# RE01_256KB register map
Vendor: Renesas Electronics Corporation; Series: RE01; File version: 1.00.01
CPU: CM0PLUS r0p1, little endian, MPU, no FPU, VTOR, 2 interrupt priority bits, 32 interrupts
Registers are 8-bit, read-write, reset 0x0 unless marked. A register's access mark holds for its fields unless they carry their own. Offsets are from the block's base; [hi:lo] are bit positions; {n}, {i} and the like mark numbered series; 'fields as' and 'values as' point back to an identical list.

## DMA — DMAC Module Activation
Base 0x40005200
0x00 DMAST — DMA Module Activation Register
  [0] DMST — DMAC Operation Enable
    0=DMAC activation is disabled; 1=DMAC activation is enabled

## DTC — Data Transfer Controller
Base 0x40005400
0x00 DTCCR reset 0x8 — DTC Control Register
  [4] RRS — DTC Transfer Information Read Skip Enable
    0=Transfer information read is not skipped; 1=Transfer information read is skipped when vector numbers match
0x04 DTCVBR 32-bit — DTC Vector Base Register
0x0C DTCST — DTC Module Start Register
  [0] DTCST — DTC Module Start
    0=DTC module stopped; 1=DTC module started
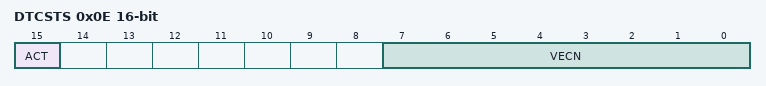
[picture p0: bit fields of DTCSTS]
0x0E DTCSTS 16-bit ro — DTC Status Register
  [15] ACT — DTC Active Flag
    0=DTC transfer operation is not in progress; 1=DTC transfer operation is in progress
  [7:0] VECN — DTC-Activating Vector Number Monitoring

## DBG — Debug Function
Base 0x4001B000
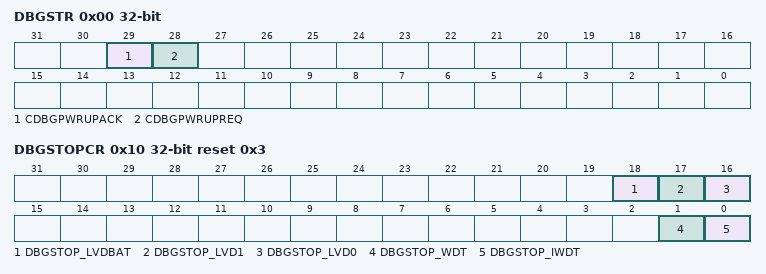
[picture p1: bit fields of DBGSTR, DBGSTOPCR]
0x00 DBGSTR 32-bit ro — Debug Status Register
  [29] CDBGPWRUPACK — Debug power-up acknowledge
    0=Debug power-up request is not acknowledged; 1=Debug power-up request is acknowledged
  [28] CDBGPWRUPREQ — Debug power-up request
    0=OCD is not requesting debug power up; 1=OCD is requesting debug power up
0x10 DBGSTOPCR 32-bit reset 0x3 — Debug Stop Control Register
  [18] DBGSTOP_LVDBAT — Mask bit for LVDBAT reset/interrupt
    0=Enable LVDBAT reset/interrupt; 1=Mask LVDBAT reset/interrupt
  [17] DBGSTOP_LVD1 — Mask bit for LVD1 reset/interrupt
    0=Enable LVD1 reset/interrupt; 1=Mask LVD1 reset/interrupt
  [16] DBGSTOP_LVD0 — Mask bit for LVD0 reset
    0=Enable LVD0 reset; 1=Mask LVD0 reset
  [1] DBGSTOP_WDT — Mask bit for WDT reset/interrupt
    0=Enable WDT reset/interrupt; 1=Mask WDT reset/interrupt and stop WDT count when CPU is in OCD break mode
  [0] DBGSTOP_IWDT — Mask bit for IWDT reset/interrupt
    0=Enable IWDT reset/interrupt; 1=Mask IWDT reset/interrupt and stop IWDT count when CPU is in OCD break mode

## SYSF — System /Flash Control
Base 0x4001C000
0x11C FLWT — Flash Wait Cycle Register
  [2:0] FLWT — Flash Wait Cycle
    0=No cycles of waiting (ICLK ≤ 32 MHz); 1=One cycle of waiting (ICLK ≤ 64 MHz); other=Others (Setting prohibited)

## EHC — Energy Harvesting Controller
Base 0x4001E180
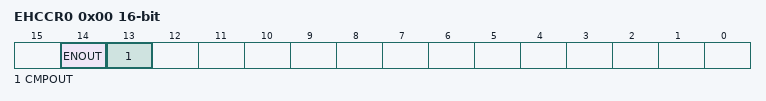
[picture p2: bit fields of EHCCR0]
0x00 EHCCR0 16-bit (reset mask 0x9FFF) — EHC Control Register 0
  [14] ENOUT ro — Power Generating Element Status Flag
    0=The power generating element connected to the VSC_VCC pin is not generating power; 1=The power generating element connected to the VSC_VCC pin is generating power
  [13] CMPOUT ro — Charging Target Monitoring Flag
    0=The storage capacitor connected to the VCC_SU pin from the power generating element connected to the VSC_VCC pin is being charged; 1=The secondary battery connected to the VBAT_EHC pin from the power generating element connected to the VSC_VCC pin is being charged
0x02 EHCCR1 — EHC Control Register 1
  [0] QUICKMODE — Steady Operation Setting
    0=Initial charging or EHC initialization setting; 1=Steady operation or EHC unused setting

## PORT0 — Port 0 Control Registers
Base 0x40040000
Same registers: PORT1 0x40040020, PORT5 0x400400A0, PORT6 0x400400C0, PORT7 0x400400E0, PORT8 0x40040100
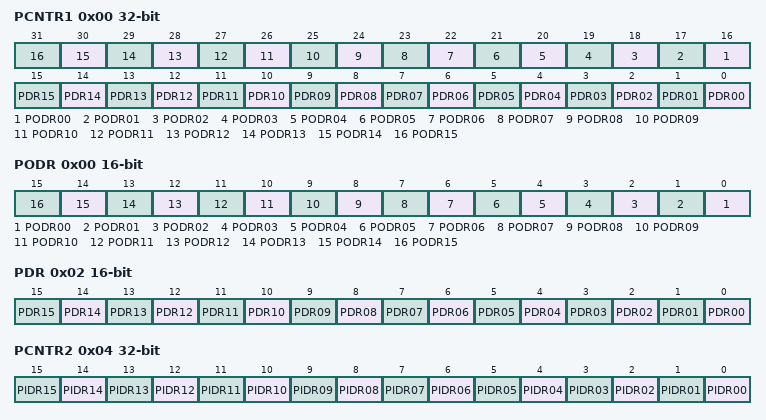
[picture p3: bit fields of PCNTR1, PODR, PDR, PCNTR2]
0x00 PCNTR1 32-bit — Port Control Register 1
  [n+16] PODR{n:02} (n=0..15) — Pmn Output Data Store
    0=Low output; 1=High output
  [n] PDR{n:02} (n=0..15) — Pmn Direction Control
    0=Input (functions as an input pin); 1=Output (functions as an output pin)
0x00 PODR 16-bit (alternate view of PCNTR1) — Port Control Register 1
  [all] fields
    0=Low output; 1=High output
  [n] PODR{n:02} (n=0..15) — Pmn Output Data Store
0x02 PDR 16-bit (alternate view of PCNTR1) — Port Control Register 1
  [all] fields
    values as PCNTR1.PDR00
  [n] PDR{n:02} (n=0..15) — Pmn Direction Control
0x04 PCNTR2 32-bit ro reset not defined — Port Control Register 2
  [all] fields
    0=Low input; 1=High input
  [n] PIDR{n:02} (n=0..15) — Pmn Input Data
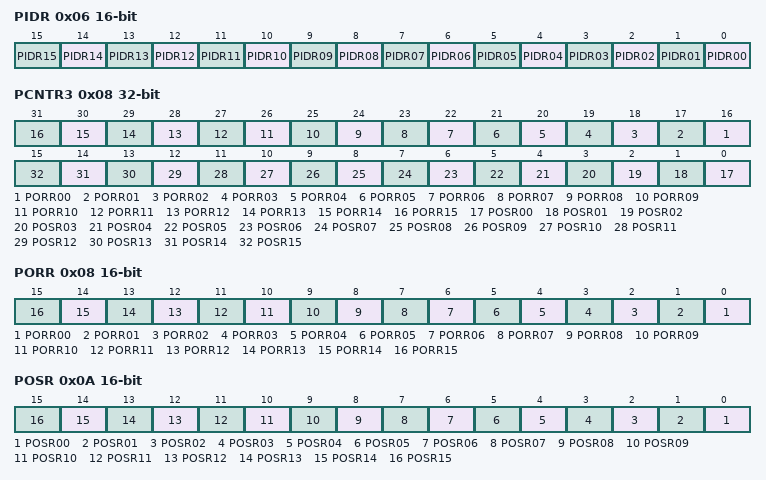
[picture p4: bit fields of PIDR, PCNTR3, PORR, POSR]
0x06 PIDR 16-bit ro reset not defined (alternate view of PCNTR2) — Port Control Register 2
  fields as PCNTR2
0x08 PCNTR3 32-bit wo — Port Control Register 3
  [n+16] PORR{n:02} (n=0..15) — Pmn Output Low Set
    0=No affect on output; 1=Low output
  [n] POSR{n:02} (n=0..15) — Pmn Output High Set
    0=No affect on output; 1=High output
0x08 PORR 16-bit wo (alternate view of PCNTR3) — Port Control Register 3
  [all] fields
    0=No affect on output; 1=Low output
  [n] PORR{n:02} (n=0..15) — Pmn Output Low Set
0x0A POSR 16-bit wo (alternate view of PCNTR3) — Port Control Register 3
  [all] fields
    0=No affect on output; 1=High output
  [n] POSR{n:02} (n=0..15) — Pmn Output High Set
